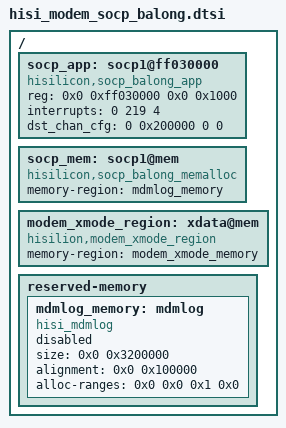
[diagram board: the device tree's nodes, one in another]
/*
 * Hisilicon Ltd Balong SOC
 */

/include/ "skeleton.dtsi"

/{
	socp_app:socp1@ff030000 {
		compatible = "hisilicon,socp_balong_app";
		reg = <0x0 0xff030000 0x0 0x1000>;
		interrupts = <0 219 4>;
		dst_chan_cfg = <0 0x200000 0 0>;
		status = "ok";
	};

	socp_mem:socp1@mem {
		 compatible = "hisilicon,socp_balong_memalloc";
		 memory-region = <&mdmlog_memory>; 
	 };
	modem_xmode_region:xdata@mem {
		compatible = "hisilion,modem_xmode_region";
		memory-region = <&modem_xmode_memory>; 
	 };
		
	reserved-memory {
		#address-cells = <2>;
		#size-cells = <2>;
		ranges;

    mdmlog_memory:mdmlog {
			size = <0x0 0x3200000>;
			alignment = <0x0 0x100000>;
			alloc-ranges = <0x0 0x0 0x1 0x0>;
			compatible = "hisi_mdmlog";
			status =" disabled";
		};
   
	};
	
};
